# cslr_ata_001 register map
Vendor: Texas Instruments
Peripheral module from a debugger description file.
Registers are 32-bit, access not given, reset values left out (the file's numbers can be read two ways) unless marked. A register's access mark holds for its fields unless they carry their own. Offsets are as the file gives them; lines under a group give offsets from that group; [hi:lo] are bit positions; {n}, {i} and the like mark numbered series; 'fields as' and 'values as' point back to an identical list; <NAME> marks a mode.

## ATA — IDE/ATA host controller to interface to IDE/ATA devices
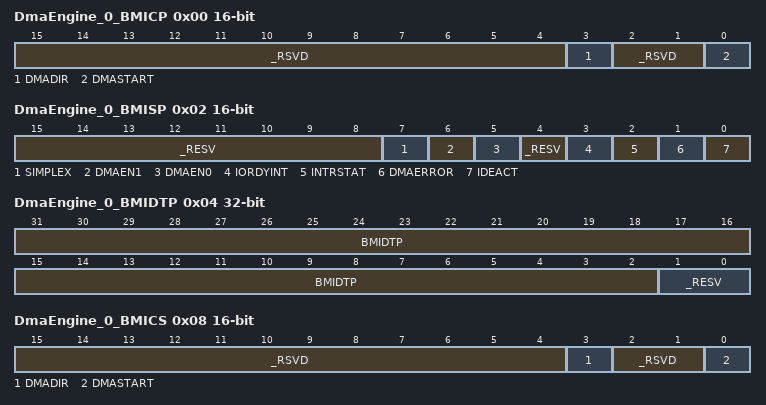
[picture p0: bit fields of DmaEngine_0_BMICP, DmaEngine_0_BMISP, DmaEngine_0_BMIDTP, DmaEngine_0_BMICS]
0x00 DmaEngine_0_BMICP 16-bit — Primary Channel Bus Master IDE Command Register
  [15:4] _RSVD — (access N)
  [3] DMADIR rw — DMA Data Transfer Direction
    0=DMAREAD (Write to IDE device); 1=DMAWRITE (Read from IDE device)
  [2:1] _RSVD — (access N)
  [0] DMASTART rw — DMA Start/Stop Control
    1=START (Begin DMA operation); 0=STOP (Terminate DMA operation)
0x02 DmaEngine_0_BMISP 16-bit — Primary Channel Bus Master IDE Status Register
  [15:8] _RESV — (access N)
  [7] SIMPLEX ro — Simplex DMA Mode
    0=DUAL (Can be simultaneously active); 1=SINGLE (Only one channel active at a time)
  [6] DMAEN1 rw — Device 1 DMA Enable
    0=DISABLE (Device 1 not capable of DMA operation); 1=ENABLE (Device 1 capable of DMA operation)
  [5] DMAEN0 rw — Device 0 DMA Enable
    0=DISABLE (Device 0 not capable of DMA operation); 1=ENABLE (Device 0 capable of DMA operation)
  [4] _RESV — (access N)
  [3] IORDYINT — IORDY Timeout (access RC)
    1=ENABLED (IORDY Timer functionality enabled); 1=CLEAR (Write 1 to clear the bit)
  [2] INTRSTAT — IDE Interrupt Status (access RC)
    1=CLEAR (Write 1 to clear the bit); 1=ACTIVE (IDE Interrupt Active)
  [1] DMAERROR — DMA Error (access RC)
    1=CLEAR (Write 1 to clear the bit); 1=ACTIVE (Set due to buffer underflow/overflow)
  [0] IDEACT ro — IDE Active
    1=ACTIVE; 0=COMPLETE
0x04 DmaEngine_0_BMIDTP — Primary Channel Bus Master Table Pointer Register
  [31:2] BMIDTP rw — Descriptor Base Address Pointer
  [1:0] _RESV — (access N)
0x08 DmaEngine_0_BMICS 16-bit — Secondary Channel Bus Master IDE Command Register
  fields as DmaEngine_0_BMICP
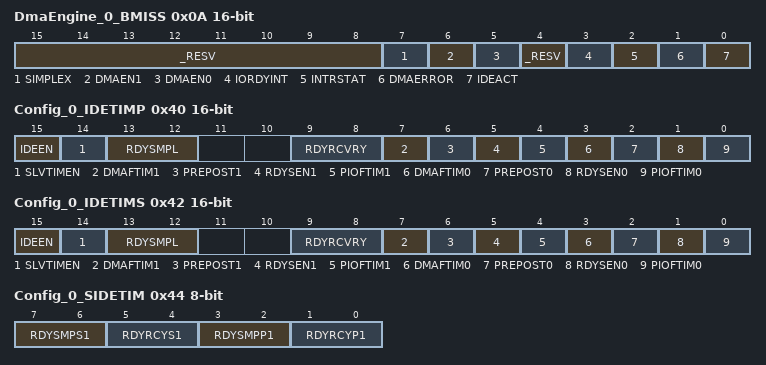
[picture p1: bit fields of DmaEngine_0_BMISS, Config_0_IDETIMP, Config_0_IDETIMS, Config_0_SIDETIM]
0x0A DmaEngine_0_BMISS 16-bit — Secondary Channel Bus Master IDE Status Register
  fields as DmaEngine_0_BMISP
0x0C DmaEngine_0_BMIDTPS — Secondary Channel Bus Master Table Pointer Register
  [31:2] BMIDTP rw — Descriptor Base Address Pointer
0x40 Config_0_IDETIMP 16-bit — Primary IDE Channel Timing Register
  [15] IDEEN rw — IDE Decode Enable
    0=DISABLE (PIO transactions not decoded); 1=ENABLE (PIO transactions decoded)
  [14] SLVTIMEN rw — Slave IDE Timing Enable
    0=DISABLE; 1=ENABLE
  [13:12] RDYSMPL rw — IORDY sample point
    0=120NS; 1=100NS; 2=80NS; 3=70NS
  [9:8] RDYRCVRY rw — IORDY recovery time
    0=120NS; 1=100NS; 2=75NS; 3=50NS
  [7] DMAFTIM1 rw — Device 1 DMA fast timing enable
    0=PIOTCR (PIO and DMA use timing control registers); 1=PIOCOMP (DMA uses timing control registers, PIO uses compatible timing)
  [6] PREPOST1 rw — Device 1 PIO prefetch and postwrite enable
    0=DISABLE (PIO data prefetch and postwrite for device1 disabled); 1=ENABLE (PIO data prefetch and postwrite for device1 enabled)
  [5] RDYSEN1 rw — Device 1 IORDY sample point enable
    0=DISABLE (Device1 iordy is ignored); 1=ENABLE (iordy may extend PIO accesses to device1)
  [4] PIOFTIM1 rw — Device 1 PIO fast timing enable
    0=DISABLE (PIO data accesses to device1 use 16-bit compatible timing); 1=ENABLE (PIO data transfers to device1 depends on DMAFTIM1 value)
  [3] DMAFTIM0 rw — Device 0 DMA fast timing enable
    values as DMAFTIM1
  [2] PREPOST0 rw — Device 0 PIO prefetch and postwrite enable
    0=DISABLE (PIO data prefetch and postwrite for device0 disabled); 1=ENABLE (PIO data prefetch and postwrite for device0 enabled)
  [1] RDYSEN0 rw — Device 0 IORDY sample point enable
    0=DISABLE (Device0 iordy is ignored); 1=ENABLE (iordy may extend PIO accesses to device0)
  [0] PIOFTIM0 rw — Device 0 PIO fast timing enable
    0=DISABLE (PIO data accesses to device0 use 16-bit compatible timing); 1=ENABLE (PIO data transfers to device0 depends on DMAFTIM0 value)
0x42 Config_0_IDETIMS 16-bit — Secondary IDE Channel Timing Register
  fields as Config_0_IDETIMP
0x44 Config_0_SIDETIM 8-bit rw — Slave IDE Timing Register
  [7:6] RDYSMPS1 — Secondary device 1 IORDY sample point
    0=120NS; 1=100NS; 2=80NS; 3=70NS
  [5:4] RDYRCYS1 — Secondary device 1 IORDY recovery time
    0=120NS; 1=100NS; 2=75NS; 3=50NS
  [3:2] RDYSMPP1 — Primary device 1 IORDY sample point
    0=120NS; 1=100NS; 2=80NS; 3=70NS
  [1:0] RDYRCYP1 — Primary device 1 IORDY recovery time
    0=120NS; 1=100NS; 2=75NS; 3=50NS
0x45 Config_0_SLEWCTL 16-bit rw — IDE Slew Control Register (configuration option)
  [15:0] SLEWCTL — Slew Rate Control for data
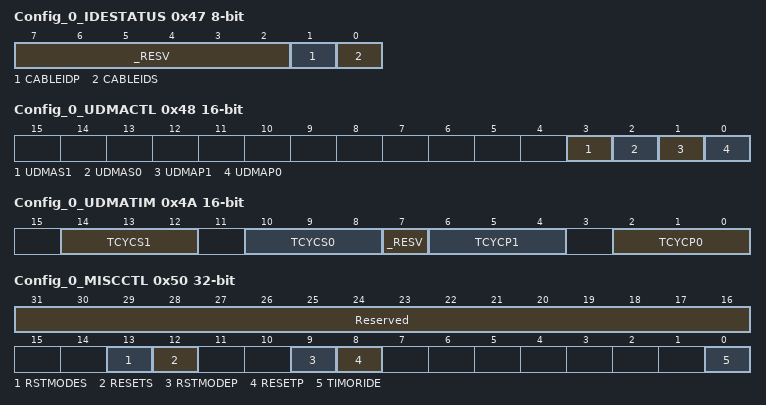
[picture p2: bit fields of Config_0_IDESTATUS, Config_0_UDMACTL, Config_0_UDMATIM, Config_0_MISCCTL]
0x47 Config_0_IDESTATUS 8-bit — IDE Status Register
  [7:2] _RESV — (access N)
  [1] CABLEIDP ro — Primary Cable ID
    0=80COND (80-conductor primary channel IDE cable detected); 1=40COND (40-conductor primary channel IDE cable detected)
  [0] CABLEIDS ro — Secondary Cable ID
    values as CABLEIDP
0x48 Config_0_UDMACTL 16-bit — Ultra DMA Control Register
  [3] UDMAS1 rw — Secondary device 1 UDMA enable
  [2] UDMAS0 rw — Secondary device 0 UDMA enable
  [1] UDMAP1 rw — Primary device 1 UDMA enable
  [0] UDMAP0 rw — Primary device 0 UDMA enable
0x4A Config_0_UDMATIM 16-bit — Ultra DMA Timing Register
  [14:12] TCYCS1 rw — Secondary device 1 cycle time
    {v}=MODE{v} (Secondary device 1 Mode {v} operation (UltraATA-33 and higher)) (v=0..3); 4=MODE4 (Secondary device 1 Mode 4 operation (UltraATA-66 and higher only)); 5=MODE5 (Secondary device 1 Mode 5 operation (UltraATA-100 and higher only)); 6=MODE6 (Secondary device 1 Mode 6 operation (UltraATA-133 only))
  [10:8] TCYCS0 rw — Secondary device 0 cycle time
    {v}=MODE{v} (Secondary device 0 Mode {v} operation (UltraATA-33 and higher)) (v=0..3); 4=MODE4 (Secondary device 0 Mode 4 operation (UltraATA-66 and higher only)); 5=MODE5 (Secondary device 0 Mode 5 operation (UltraATA-100 and higher only)); 6=MODE6 (Secondary device 0 Mode 6 operation (UltraATA-133 only))
  [7] _RESV — (access N)
  [6:4] TCYCP1 rw — Primary device 1 cycle time
    {v}=MODE{v} (Primary device 0 Mode {v} operation (UltraATA-33 and higher)) (v=0..3); 4=MODE4 (Primary device 0 Mode 4 operation (UltraATA-66 and higher only)); 5=MODE5 (Primary device 0 Mode 5 operation (UltraATA-100 and higher only)); 6=MODE6 (Primary device 0 Mode 6 operation (UltraATA-133 only))
  [2:0] TCYCP0 rw — Primary device 0 cycle time
    {v}=MODE{v} (Primary device 1 Mode {v} operation (UltraATA-33 and higher)) (v=0..3); 4=MODE4 (Primary device 1 Mode 4 operation (UltraATA-66 and higher only)); 5=MODE5 (Primary device 1 Mode 5 operation (UltraATA-100 and higher only)); 6=MODE6 (Primary device 1 Mode 6 operation (UltraATA-133 only))
0x50 Config_0_MISCCTL — Miscellaneous Control Register
  [31:16] Reserved — (access N)
  [13] RSTMODES rw — Reset pin drive mode for secondary controller
    0=OPENCOLL (RESETN pin operates in open collector mode for secondary controller); 1=PUSHPULL (RESETN pin operates in push-pull mode for secondary controller)
  [12] RESETS rw — Reset pin signal for secondary controller
    0=NEGATE (RESETN pin is negated (high voltage) for secondary controller); 1=ASSERT (RESETN pin is asserted (low voltage) for secondary controller)
  [9] RSTMODEP rw — Reset pin drive mode for primary controller
    0=OPENCOLL (RESETN pin operates in open collector mode for primary controller); 1=PUSHPULL (RESETN pin operates in push-pull mode for primary controller)
  [8] RESETP rw — Reset pin signal for primary controller
    0=NEGATE (RESETN pin is negated (high voltage) for primary controller); 1=ASSERT (RESETN pin is asserted (low voltage) for primary controller)
  [0] TIMORIDE rw — Override default IDE timing controls
    0=DISABLE (IDE interface timing is controlled by the internal timing parameters of the controller); 1=ENABLE (IDE interface timing is controlled by the timing override registers)
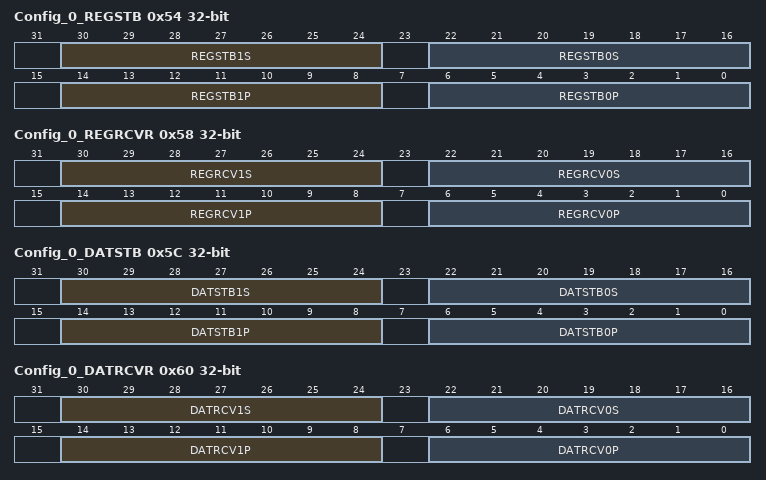
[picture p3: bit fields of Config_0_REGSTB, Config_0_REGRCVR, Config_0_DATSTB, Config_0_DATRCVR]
0x54 Config_0_REGSTB — Task File Register Strobe Timing Register
  [30:24] REGSTB1S rw — 8-bit register access slave strobe width for secondary controller
  [22:16] REGSTB0S rw — 8-bit register access master strobe width for secondary controller
  [14:8] REGSTB1P rw — 8-bit register access slave strobe width for primary controller
  [6:0] REGSTB0P rw — 8-bit register access master strobe width for primary controller
0x58 Config_0_REGRCVR — Task File Register Recovery Timing Register
  [30:24] REGRCV1S rw — 8-bit register access slave recovery time for secondary controller
  [22:16] REGRCV0S rw — 8-bit register access master recovery time for secondary controller
  [14:8] REGRCV1P rw — 8-bit register access slave recovery time for primary controller
  [6:0] REGRCV0P rw — 8-bit register access master recovery time for primary controller
0x5C Config_0_DATSTB — Data Register PIO Strobe Timing Register
  [30:24] DATSTB1S rw — Slave data register access strobe width for secondary controller
  [22:16] DATSTB0S rw — Master data register access strobe width for secondary controller
  [14:8] DATSTB1P rw — Slave data register access strobe width for primary controller
  [6:0] DATSTB0P rw — Master data register access strobe width for primary controller
0x60 Config_0_DATRCVR — Data Register PIO Recovery Timing Register
  [30:24] DATRCV1S rw — Slave data register access recovery time for secondary controller
  [22:16] DATRCV0S rw — Master data register access recovery time for secondary controller
  [14:8] DATRCV1P rw — Slave data register access recovery time for primary controller
  [6:0] DATRCV0P rw — Master data register access recovery time for primary controller
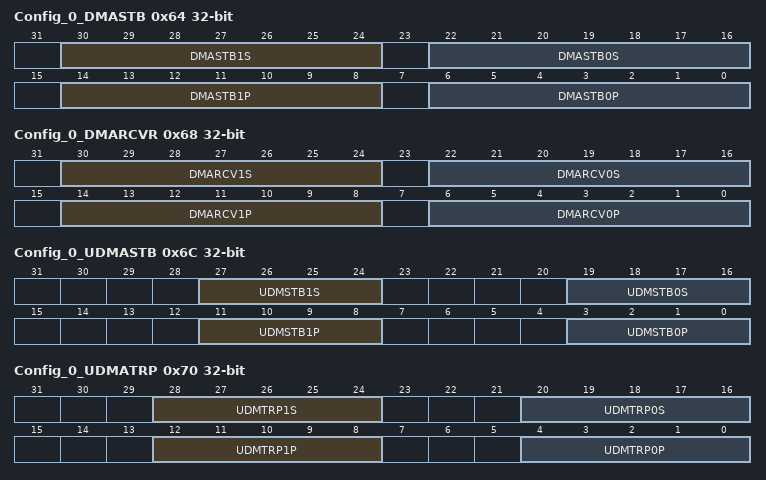
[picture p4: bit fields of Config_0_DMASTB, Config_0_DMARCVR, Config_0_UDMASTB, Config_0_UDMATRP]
0x64 Config_0_DMASTB — DMA Strobe Timing Register
  [30:24] DMASTB1S rw — Slave DMA access strobe width for secondary controller
  [22:16] DMASTB0S rw — Master DMA access strobe width for secondary controller
  [14:8] DMASTB1P rw — Slave DMA access strobe width for primary controller
  [6:0] DMASTB0P rw — Master DMA access strobe width for primary controller
0x68 Config_0_DMARCVR — DMA Recovery Timing Register
  [30:24] DMARCV1S rw — Slave DMA access recovery time for secondary controller
  [22:16] DMARCV0S rw — Master DMA access recovery time for secondary controller
  [14:8] DMARCV1P rw — Slave DMA access recovery time for primary controller
  [6:0] DMARCV0P rw — Master DMA access recovery time for primary controller
0x6C Config_0_UDMASTB — Ultra DMA Strobe Timing Register
  [27:24] UDMSTB1S rw — Slave Ultra DMA access strobe width for secondary controller
  [19:16] UDMSTB0S rw — Master Ultra DMA access strobe width for secondary controller
  [11:8] UDMSTB1P rw — Slave Ultra DMA access strobe width for primary controller
  [3:0] UDMSTB0P rw — Master Ultra DMA access strobe width for primary controller
0x70 Config_0_UDMATRP — Ultra DMA Ready-to-Stop Timing Register
  [28:24] UDMTRP1S rw — Slave Ultra DMA ready-to-pause time for secondary controller
  [20:16] UDMTRP0S rw — Master Ultra DMA ready-to-pause time for secondary controller
  [12:8] UDMTRP1P rw — Slave Ultra DMA ready-to-pause time for primary controller
  [4:0] UDMTRP0P rw — Master Ultra DMA ready-to-pause time for primary controller
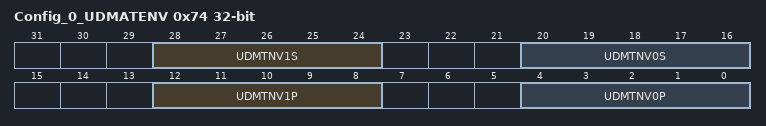
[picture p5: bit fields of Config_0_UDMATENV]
0x74 Config_0_UDMATENV — Ultra DMA Timing Envelope Register
  [28:24] UDMTNV1S rw — T-env timing parameter for slave device for secondary controller
  [20:16] UDMTNV0S rw — T-env timing parameter for master device for secondary controller
  [12:8] UDMTNV1P rw — T-env timing parameter for slave device for primary controller
  [4:0] UDMTNV0P rw — T-env timing parameter for master device for secondary controller
0x78 Config_0_IORDYTMP — Primary IO Ready Timer Configuration Register
  [17:0] IORDYTMP rw — IORDY Timeout value for Primary Controller
0x7C Config_0_IORDYTMS — Secondary IO Ready Timer Configuration Register
  [17:0] IORDYTMS rw — IORDY Timeout value for Secondary Controller
